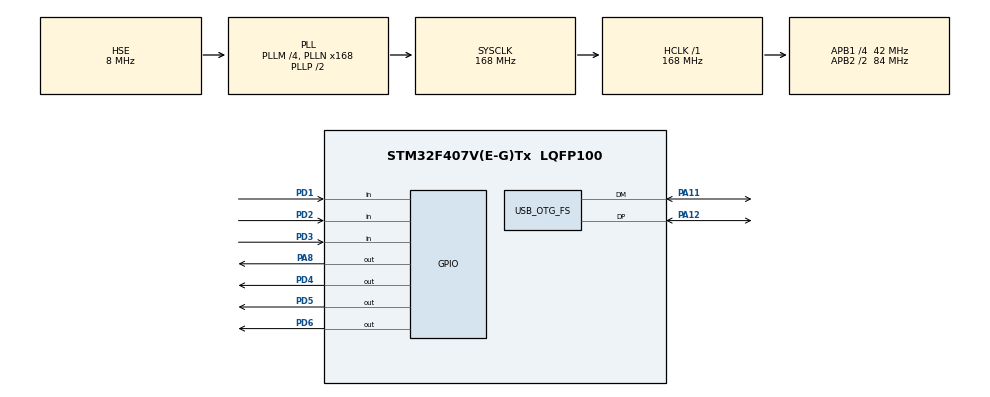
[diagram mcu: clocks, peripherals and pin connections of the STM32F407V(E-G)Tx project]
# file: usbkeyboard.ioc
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Mcu.Family=STM32F4
Mcu.Name=STM32F407V(E-G)Tx
Mcu.Package=LQFP100
NVIC.OTG_FS_IRQn=true\:0\:0\:false\:false\:true\:false\:true\:true
NVIC.PriorityGroup=NVIC_PRIORITYGROUP_4
PA11.Mode=Device_Only
PA11.Signal=USB_OTG_FS_DM
PA12.Mode=Device_Only
PA12.Signal=USB_OTG_FS_DP
PA13.Mode=Serial_Wire
PA13.Signal=SYS_JTMS-SWDIO
PA14.Mode=Serial_Wire
PA14.Signal=SYS_JTCK-SWCLK
PA8.GPIO_PuPd=GPIO_PULLUP
PA8.GPIO_Speed=GPIO_SPEED_FREQ_VERY_HIGH
PA8.PinState=GPIO_PIN_SET
PA8.Signal=GPIO_Output
PC14-OSC32_IN.Mode=LSE-External-Oscillator
PC14-OSC32_IN.Signal=RCC_OSC32_IN
PC15-OSC32_OUT.Mode=LSE-External-Oscillator
PC15-OSC32_OUT.Signal=RCC_OSC32_OUT
PD1.Signal=GPIO_Input
PD2.Signal=GPIO_Input
PD3.Signal=GPIO_Input
PD4.Signal=GPIO_Output
PD5.Signal=GPIO_Output
PD6.Signal=GPIO_Output
PH0-OSC_IN.Mode=HSE-External-Oscillator
PH0-OSC_IN.Signal=RCC_OSC_IN
PH1-OSC_OUT.Mode=HSE-External-Oscillator
PH1-OSC_OUT.Signal=RCC_OSC_OUT
ProjectManager.HeapSize=0x2000
ProjectManager.StackSize=0x2000
ProjectManager.TargetToolchain=Makefile
RCC.48MHZClocksFreq_Value=48000000
RCC.AHBFreq_Value=168000000
RCC.APB1CLKDivider=RCC_HCLK_DIV4
RCC.APB1Freq_Value=42000000
RCC.APB1TimFreq_Value=84000000
RCC.APB2CLKDivider=RCC_HCLK_DIV2
RCC.APB2Freq_Value=84000000
RCC.APB2TimFreq_Value=168000000
RCC.CortexFreq_Value=168000000
RCC.EnbaleCSS=true
RCC.HCLKFreq_Value=168000000
RCC.HSE_VALUE=8000000
RCC.HSI_VALUE=16000000
RCC.PLLM=4
RCC.PLLN=168
RCC.PLLQ=7
RCC.SYSCLKFreq_VALUE=168000000
RCC.SYSCLKSource=RCC_SYSCLKSOURCE_PLLCLK
RCC.VCOOutputFreq_Value=336000000
USB_DEVICE.CLASS_NAME_FS=HID
USB_DEVICE.USBD_MAX_STR_DESC_SIZ-HID_FS=1024
USB_DEVICE.USBD_SELF_POWERED-HID_FS=0
USB_DEVICE.VirtualMode-HID_FS=Hid
USB_DEVICE.VirtualModeFS=Hid_FS
USB_OTG_FS.VirtualMode=Device_Only
VP_USB_DEVICE_VS_USB_DEVICE_HID_FS.Mode=HID_FS
board=custom

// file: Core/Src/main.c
/* USER CODE BEGIN Header */
/**
  ******************************************************************************
  * @file           : main.c
  * @brief          : Main program body
  ******************************************************************************
  * @attention
  *
  * Copyright (c) 2025 STMicroelectronics.
  * All rights reserved.
  *
  * This software is licensed under terms that can be found in the LICENSE file
  * in the root directory of this software component.
  * If no LICENSE file comes with this software, it is provided AS-IS.
  *
  ******************************************************************************
  */
/* USER CODE END Header */
#include "main.h"
#include "usb_device.h"
#include "gpio.h"

/* USER CODE BEGIN Includes */
#include "usbd_hid.h"
/* USER CODE END Includes */

/* USER CODE BEGIN PV */
extern USBD_HandleTypeDef hUsbDeviceFS; // 引用 USB 设备句柄

// 键盘报文结构：8个字节
// Byte 0: 特殊键 (Ctrl, Shift, Alt, Gui)
// Byte 1: 保留 (0x00)
// Byte 2~7: 普通按键键值 (最多同时按6个键)
uint8_t keyboardHID[8] = {0};
/* USER CODE END PV */

void SystemClock_Config(void);

int main(void)
{

  /* MCU Configuration--------------------------------------------------------*/

  /* Reset of all peripherals, Initializes the Flash interface and the Systick. */
  HAL_Init();

  /* Configure the system clock */
  SystemClock_Config();

  /* Initialize all configured peripherals */
  MX_GPIO_Init();
  MX_USB_DEVICE_Init();

  /* Infinite loop */
  /* USER CODE BEGIN WHILE */
while (1)
{
    // --- 动作 1：按下 'a' ---

    HAL_GPIO_WritePin(GPIOA, GPIO_PIN_8, GPIO_PIN_RESET);
    // // 清空缓冲区
    // keyboardHID[0] = 0; // 无修饰键
    // keyboardHID[2] = 0x04; // 0x04 是 'a' 的 HID 键值 (不是 ASCII 码!)

    // // 发送报文
    // USBD_HID_SendReport(&hUsbDeviceFS, keyboardHID, 8);

    // 延时 (模拟按键按下的持续时间)
    HAL_Delay(500);

    // // --- 动作 2：松开按键 ---

    // // 必须发送一个全 0 的报文，告诉电脑我已经松手了
    // keyboardHID[2] = 0x00;
    // USBD_HID_SendReport(&hUsbDeviceFS, keyboardHID, 8);
    HAL_GPIO_WritePin(GPIOA, GPIO_PIN_8, GPIO_PIN_SET);
    HAL_Delay(500);
    // --- 动作 3：等待 1 秒再按 ---
    // HAL_Delay(1000);

    /* USER CODE END WHILE */

  }
}

void SystemClock_Config(void)
{
  RCC_OscInitTypeDef RCC_OscInitStruct = {0};
  RCC_ClkInitTypeDef RCC_ClkInitStruct = {0};

  /** Configure the main internal regulator output voltage
  */
  __HAL_RCC_PWR_CLK_ENABLE();
  __HAL_PWR_VOLTAGESCALING_CONFIG(PWR_REGULATOR_VOLTAGE_SCALE1);

  /** Initializes the RCC Oscillators according to the specified parameters
  * in the RCC_OscInitTypeDef structure.
  */
  RCC_OscInitStruct.OscillatorType = RCC_OSCILLATORTYPE_HSE;
  RCC_OscInitStruct.HSEState = RCC_HSE_ON;
  RCC_OscInitStruct.PLL.PLLState = RCC_PLL_ON;
  RCC_OscInitStruct.PLL.PLLSource = RCC_PLLSOURCE_HSE;
  RCC_OscInitStruct.PLL.PLLM = 4;
  RCC_OscInitStruct.PLL.PLLN = 168;
  RCC_OscInitStruct.PLL.PLLP = RCC_PLLP_DIV2;
  RCC_OscInitStruct.PLL.PLLQ = 7;
  if (HAL_RCC_OscConfig(&RCC_OscInitStruct) != HAL_OK)
  {
    Error_Handler();
  }

  /** Initializes the CPU, AHB and APB buses clocks
  */
  RCC_ClkInitStruct.ClockType = RCC_CLOCKTYPE_HCLK|RCC_CLOCKTYPE_SYSCLK
                              |RCC_CLOCKTYPE_PCLK1|RCC_CLOCKTYPE_PCLK2;
  RCC_ClkInitStruct.SYSCLKSource = RCC_SYSCLKSOURCE_PLLCLK;
  RCC_ClkInitStruct.AHBCLKDivider = RCC_SYSCLK_DIV1;
  RCC_ClkInitStruct.APB1CLKDivider = RCC_HCLK_DIV4;
  RCC_ClkInitStruct.APB2CLKDivider = RCC_HCLK_DIV2;

  if (HAL_RCC_ClockConfig(&RCC_ClkInitStruct, FLASH_LATENCY_5) != HAL_OK)
  {
    Error_Handler();
  }

  /** Enables the Clock Security System
  */
  HAL_RCC_EnableCSS();
}

void Error_Handler(void)
{
  __disable_irq();
  while (1)
  {
  }
}
